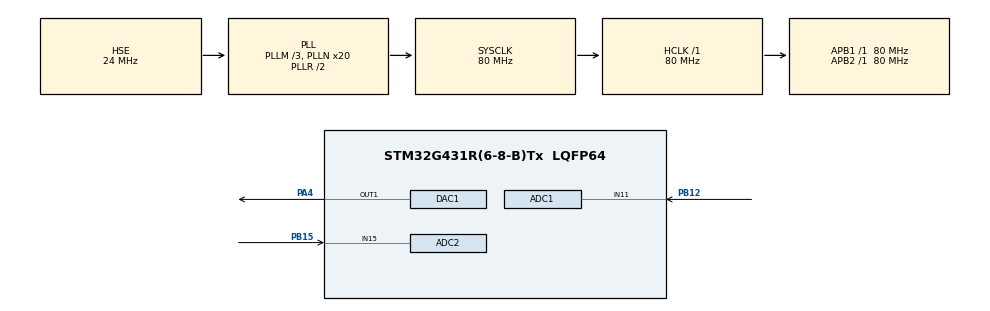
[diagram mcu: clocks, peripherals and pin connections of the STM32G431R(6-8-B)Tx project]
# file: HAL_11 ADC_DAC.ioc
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ADC1.Channel-0\#ChannelRegularConversion=ADC_CHANNEL_11
ADC1.NbrOfConversion=1
ADC1.NbrOfConversionFlag=1
ADC1.OffsetNumber-0\#ChannelRegularConversion=ADC_OFFSET_NONE
ADC1.Rank-0\#ChannelRegularConversion=1
ADC1.SamplingTime-0\#ChannelRegularConversion=ADC_SAMPLETIME_640CYCLES_5
ADC1.master=1
ADC2.Channel-0\#ChannelRegularConversion=ADC_CHANNEL_15
ADC2.NbrOfConversionFlag=1
ADC2.OffsetNumber-0\#ChannelRegularConversion=ADC_OFFSET_NONE
ADC2.Rank-0\#ChannelRegularConversion=1
ADC2.SamplingTime-0\#ChannelRegularConversion=ADC_SAMPLETIME_640CYCLES_5
Mcu.Family=STM32G4
Mcu.Name=STM32G431R(6-8-B)Tx
Mcu.Package=LQFP64
NVIC.ADC1_2_IRQn=true\:0\:0\:false\:false\:true\:true\:true
NVIC.PriorityGroup=NVIC_PRIORITYGROUP_4
PA4.Signal=COMP_DAC11_group
PB12.Mode=IN11-Single-Ended
PB12.Signal=ADC1_IN11
PB15.Mode=IN15-Single-Ended
PB15.Signal=ADC2_IN15
PF0-OSC_IN.Mode=HSE-External-Oscillator
PF0-OSC_IN.Signal=RCC_OSC_IN
PF1-OSC_OUT.Mode=HSE-External-Oscillator
PF1-OSC_OUT.Signal=RCC_OSC_OUT
ProjectManager.HeapSize=0x200
ProjectManager.StackSize=0x400
ProjectManager.TargetToolchain=MDK-ARM V5.27
RCC.ADC12Freq_Value=80000000
RCC.AHBFreq_Value=80000000
RCC.APB1Freq_Value=80000000
RCC.APB1TimFreq_Value=80000000
RCC.APB2Freq_Value=80000000
RCC.APB2TimFreq_Value=80000000
RCC.CortexFreq_Value=80000000
RCC.EXTERNAL_CLOCK_VALUE=12288000
RCC.HCLKFreq_Value=80000000
RCC.HSE_VALUE=24000000
RCC.HSI48_VALUE=48000000
RCC.HSI_VALUE=16000000
RCC.LSE_VALUE=32768
RCC.PLLM=RCC_PLLM_DIV3
RCC.PLLN=20
RCC.PLLSourceVirtual=RCC_PLLSOURCE_HSE
RCC.SYSCLKFreq_VALUE=80000000
RCC.SYSCLKSource=RCC_SYSCLKSOURCE_PLLCLK
RCC.USBFreq_Value=80000000
RCC.VCOOutputFreq_Value=160000000
SH.COMP_DAC11_group.0=DAC1_OUT1,DAC_OUT1
VP_SYS_VS_DBSignals.Mode=DisableDeadBatterySignals
board=custom

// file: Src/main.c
/* USER CODE BEGIN Header */
/**
  ******************************************************************************
  * @file           : main.c
  * @brief          : Main program body
  ******************************************************************************
  * @attention
  *
  * <h2><center>&copy; Copyright (c) 2024 STMicroelectronics.
  * All rights reserved.</center></h2>
  *
  * This software component is licensed by ST under BSD 3-Clause license,
  * the "License"; You may not use this file except in compliance with the
  * License. You may obtain a copy of the License at:
  *                        opensource.org/licenses/BSD-3-Clause
  *
  ******************************************************************************
  */
/* USER CODE END Header */

#include "main.h"
#include "adc.h"
#include "dac.h"
#include "gpio.h"

/* USER CODE BEGIN Includes */
#include <stdio.h>
#include "lcd_hal.h"
/* USER CODE END Includes */

/* USER CODE BEGIN PV */
uint8_t str[20];
/* USER CODE END PV */

void SystemClock_Config(void);

/* USER CODE BEGIN 0 */
uint16_t GetADC_R37(void)
{
	uint16_t adc;//0~4096

	HAL_ADC_Start(&hadc2);//开始转换
	HAL_ADC_PollForConversion(&hadc2, 10);//等待转换完成
	adc = HAL_ADC_GetValue(&hadc2);//得到转换值
	HAL_ADC_Stop(&hadc2);//停止转换

	return adc;
}
uint16_t GetADC_R38(void)
{
	uint16_t adc;//0~4096

	HAL_ADC_Start(&hadc1);//开始转换
	HAL_ADC_PollForConversion(&hadc1, 10);//等待转换完成
	adc = HAL_ADC_GetValue(&hadc1);//得到转换值
	HAL_ADC_Stop(&hadc1);//停止转换

	return adc;
}

void DAC_SetVol(float Vol)
{
	uint16_t temp;
	temp = Vol * 4096 / 3.3f;
	HAL_DAC_SetValue(&hdac1, DAC_CHANNEL_1, DAC_ALIGN_12B_R, temp);
}
/* USER CODE END 0 */

int main(void)
{

  /* MCU Configuration--------------------------------------------------------*/

  /* Reset of all peripherals, Initializes the Flash interface and the Systick. */
  HAL_Init();

  /* Configure the system clock */
  SystemClock_Config();

  /* USER CODE BEGIN SysInit */
  LCD_Init();
  /* USER CODE END SysInit */

  /* Initialize all configured peripherals */
  MX_GPIO_Init();
  MX_ADC1_Init();
  MX_ADC2_Init();
  MX_DAC1_Init();
  /* USER CODE BEGIN 2 */
  HAL_DAC_Start(&hdac1, DAC_CHANNEL_1);

  DAC_SetVol(1.5);
  /* USER CODE END 2 */

  /* Infinite loop */
  /* USER CODE BEGIN WHILE */
  while (1)
  {
	sprintf((char *)str, "  ADC(R37):%.2fV", GetADC_R37() * 3.3 / 4096);
	LCD_DisplayStringLine(Line7, (uint8_t *)str);
	sprintf((char *)str, "  ADC(R38):%.2fV", GetADC_R38() * 3.3 / 4096);
	LCD_DisplayStringLine(Line8, (uint8_t *)str);
    /* USER CODE END WHILE */

  }
}

void SystemClock_Config(void)
{
  RCC_OscInitTypeDef RCC_OscInitStruct = {0};
  RCC_ClkInitTypeDef RCC_ClkInitStruct = {0};
  RCC_PeriphCLKInitTypeDef PeriphClkInit = {0};

  /** Configure the main internal regulator output voltage
  */
  HAL_PWREx_ControlVoltageScaling(PWR_REGULATOR_VOLTAGE_SCALE1);
  /** Initializes the CPU, AHB and APB busses clocks
  */
  RCC_OscInitStruct.OscillatorType = RCC_OSCILLATORTYPE_HSE;
  RCC_OscInitStruct.HSEState = RCC_HSE_ON;
  RCC_OscInitStruct.PLL.PLLState = RCC_PLL_ON;
  RCC_OscInitStruct.PLL.PLLSource = RCC_PLLSOURCE_HSE;
  RCC_OscInitStruct.PLL.PLLM = RCC_PLLM_DIV3;
  RCC_OscInitStruct.PLL.PLLN = 20;
  RCC_OscInitStruct.PLL.PLLP = RCC_PLLP_DIV2;
  RCC_OscInitStruct.PLL.PLLQ = RCC_PLLQ_DIV2;
  RCC_OscInitStruct.PLL.PLLR = RCC_PLLR_DIV2;
  if (HAL_RCC_OscConfig(&RCC_OscInitStruct) != HAL_OK)
  {
    Error_Handler();
  }
  /** Initializes the CPU, AHB and APB busses clocks
  */
  RCC_ClkInitStruct.ClockType = RCC_CLOCKTYPE_HCLK|RCC_CLOCKTYPE_SYSCLK
                              |RCC_CLOCKTYPE_PCLK1|RCC_CLOCKTYPE_PCLK2;
  RCC_ClkInitStruct.SYSCLKSource = RCC_SYSCLKSOURCE_PLLCLK;
  RCC_ClkInitStruct.AHBCLKDivider = RCC_SYSCLK_DIV1;
  RCC_ClkInitStruct.APB1CLKDivider = RCC_HCLK_DIV1;
  RCC_ClkInitStruct.APB2CLKDivider = RCC_HCLK_DIV1;

  if (HAL_RCC_ClockConfig(&RCC_ClkInitStruct, FLASH_LATENCY_3) != HAL_OK)
  {
    Error_Handler();
  }
  /** Initializes the peripherals clocks
  */
  PeriphClkInit.PeriphClockSelection = RCC_PERIPHCLK_ADC12;
  PeriphClkInit.Adc12ClockSelection = RCC_ADC12CLKSOURCE_SYSCLK;
  if (HAL_RCCEx_PeriphCLKConfig(&PeriphClkInit) != HAL_OK)
  {
    Error_Handler();
  }
}

void Error_Handler(void)
{
}

/************************ (C) COPYRIGHT STMicroelectronics *****END OF FILE****/
